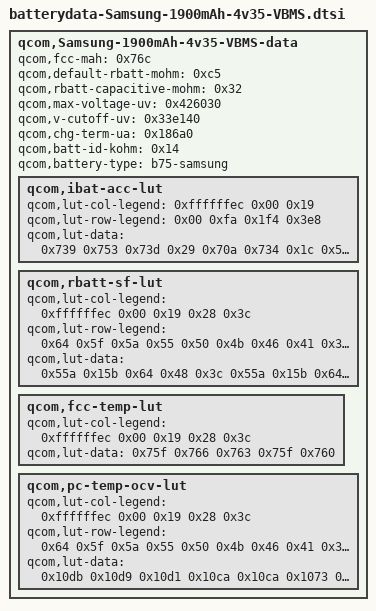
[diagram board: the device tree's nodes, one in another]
/* Copyright (c) 2018, The Linux Foundation. All rights reserved.
*  Copyright (c) 2018, Ketut P. Kumajaya.
*  Copyright (c) 2020, the_shahnawaz_sheikh (sheikhshahnawaz41299).
*
* This program is free software; you can redistribute it and/or modify
* it under the terms of the GNU General Public License version 2 and
* only version 2 as published by the Free Software Foundation.
*
* This program is distributed in the hope that it will be useful,
* but WITHOUT ANY WARRANTY; without even the implied warranty of
* MERCHANTABILITY or FITNESS FOR A PARTICULAR PURPOSE.  See the
* GNU General Public License for more details.
*/

qcom,Samsung-1900mAh-4v35-VBMS-data {
	qcom,fcc-mah = <0x76c>;
	qcom,default-rbatt-mohm = <0xc5>;
	qcom,rbatt-capacitive-mohm = <0x32>;
	qcom,max-voltage-uv = <0x426030>;
	qcom,v-cutoff-uv = <0x33e140>;
	qcom,chg-term-ua = <0x186a0>;
	qcom,batt-id-kohm = <0x14>;
	qcom,battery-type = "b75-samsung";

	qcom,ibat-acc-lut {
		qcom,lut-col-legend = <0xffffffec 0x00 0x19>;
		qcom,lut-row-legend = <0x00 0xfa 0x1f4 0x3e8>;
		qcom,lut-data = <0x739 0x753 0x73d 0x29 0x70a 0x734 0x1c 0x5d8 0x72a 0x06 0x329 0x6ea>;
	};

	qcom,rbatt-sf-lut {
		qcom,lut-col-legend = <0xffffffec 0x00 0x19 0x28 0x3c>;
		qcom,lut-row-legend = <0x64 0x5f 0x5a 0x55 0x50 0x4b 0x46 0x41 0x3c 0x37 0x32 0x2d 0x28 0x23 0x1e 0x19 0x14 0x10 0x0d 0x0b 0x0a 0x09 0x08 0x07 0x06 0x05 0x04 0x03 0x02 0x01>;
		qcom,lut-data = <0x55a 0x15b 0x64 0x48 0x3c 0x55a 0x15b 0x64 0x48 0x3c 0x4e9 0x158 0x65 0x49 0x3d 0x4b8 0x153 0x67 0x4b 0x3f 0x486 0x153 0x6a 0x4e 0x41 0x428 0x14e 0x71 0x52 0x43 0x41b 0x122 0x73 0x56 0x45 0x40e 0x126 0x7b 0x5a 0x48 0x410 0x122 0x6c 0x5f 0x4d 0x41d 0x120 0x5f 0x4c 0x44 0x434 0x120 0x5d 0x47 0x3d 0x454 0x125 0x5d 0x49 0x3e 0x475 0x12d 0x60 0x4a 0x41 0x49c 0x13d 0x62 0x4c 0x44 0x4c9 0x151 0x65 0x4d 0x43 0x500 0x167 0x68 0x4c 0x3f 0x545 0x17a 0x68 0x4a 0x3f 0x5a2 0x18c 0x66 0x4a 0x3f 0x62c 0x1a3 0x64 0x49 0x3d 0x66e 0x1b5 0x66 0x4b 0x3f 0x628 0x1ae 0x67 0x4c 0x41 0x5cc 0x1b3 0x69 0x4e 0x42 0x658 0x1c4 0x6d 0x51 0x43 0x704 0x1d7 0x72 0x53 0x45 0x7db 0x1ee 0x76 0x53 0x45 0x902 0x205 0x76 0x51 0x43 0xab3 0x218 0x76 0x52 0x43 0xe33 0x23c 0x7d 0x58 0x47 0x30bc 0x275 0x90 0x7a 0x57 0x30bc 0x275 0x90 0x7a 0x57>;
	};

	qcom,fcc-temp-lut {
		qcom,lut-col-legend = <0xffffffec 0x00 0x19 0x28 0x3c>;
		qcom,lut-data = <0x75f 0x766 0x763 0x75f 0x760>;
	};

	qcom,pc-temp-ocv-lut {
		qcom,lut-col-legend = <0xffffffec 0x00 0x19 0x28 0x3c>;
		qcom,lut-row-legend = <0x64 0x5f 0x5a 0x55 0x50 0x4b 0x46 0x41 0x3c 0x37 0x32 0x2d 0x28 0x23 0x1e 0x19 0x14 0x10 0x0d 0x0b 0x0a 0x09 0x08 0x07 0x06 0x05 0x04 0x03 0x02 0x01 0x00>;
		qcom,lut-data = <0x10db 0x10d9 0x10d1 0x10ca 0x10ca 0x1073 0x1091 0x1093 0x108e 0x108e 0x102a 0x1059 0x105c 0x1057 0x1057 0x1002 0x1025 0x1027 0x1022 0x1022 0xfcf 0xff5 0xff4 0xfef 0xff0 0xf6e 0xfbe 0xfc8 0xfc2 0xfc0 0xf43 0xf6a 0xf8c 0xf95 0xf95 0xf1c 0xf4c 0xf70 0xf6f 0xf6e 0xf02 0xf2b 0xf40 0xf49 0xf4b 0xef0 0xf0d 0xf16 0xf18 0xf1c 0xee1 0xef3 0xef9 0xef9 0xef9 0xed4 0xedd 0xee3 0xee3 0xee3 0xec6 0xecf 0xed2 0xed1 0xed1 0xeb8 0xec5 0xec4 0xec3 0xec2 0xeab 0xebc 0xebb 0xeb7 0xeb2 0xe9c 0xeb0 0xeb2 0xea9 0xe9d 0xe8b 0xe9c 0xea1 0xe95 0xe89 0xe7a 0xe89 0xe84 0xe79 0xe6e 0xe69 0xe7d 0xe6f 0xe66 0xe5a 0xe5b 0xe76 0xe6a 0xe61 0xe55 0xe53 0xe73 0xe68 0xe60 0xe55 0xe48 0xe70 0xe67 0xe60 0xe54 0xe3b 0xe6d 0xe66 0xe5e 0xe53 0xe2b 0xe69 0xe64 0xe5c 0xe50 0xe16 0xe62 0xe5f 0xe51 0xe47 0xdf9 0xe52 0xe4a 0xe34 0xe2b 0xdce 0xe31 0xe1d 0xdff 0xdfa 0xd8d 0xdf8 0xdda 0xdb6 0xdb5 0xd25 0xda2 0xd7b 0xd54 0xd55 0xcab 0xd0e 0xcf8 0xcc4 0xcb3 0xc47 0xbb8 0xbf5 0xbf3 0xbbd>;
	};
};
